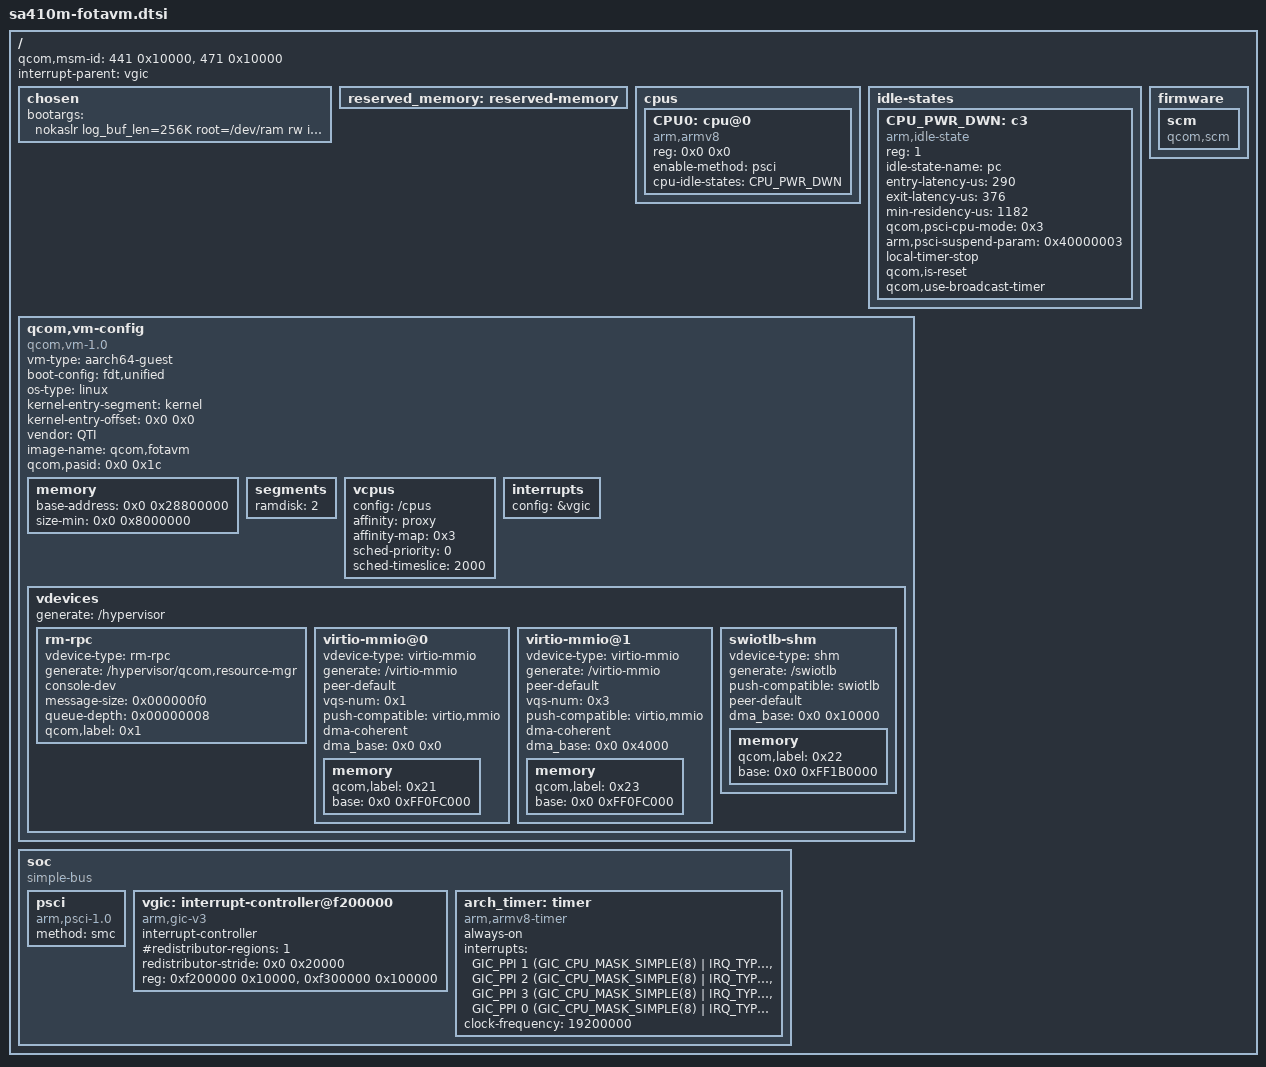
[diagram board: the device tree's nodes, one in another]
#include <dt-bindings/interrupt-controller/arm-gic.h>

/ {
	#address-cells = <0x2>;
	#size-cells = <0x2>;
	qcom,msm-id = <441 0x10000>, <471 0x10000>;
	interrupt-parent = <&vgic>;

	chosen {
		bootargs = "nokaslr log_buf_len=256K root=/dev/ram rw init=/init console=hvc0 loglevel=8";
	};

	reserved_memory: reserved-memory {
		#address-cells = <2>;
		#size-cells = <2>;
		ranges;
	};

	cpus {
		#address-cells = <0x2>;
		#size-cells = <0x0>;

		CPU0: cpu@0 {
			compatible = "arm,armv8";
			reg = <0x0 0x0>;
			device_type = "cpu";
			enable-method = "psci";
			cpu-idle-states = <&CPU_PWR_DWN>;
		};
	};

	idle-states {
		CPU_PWR_DWN: c3 {  /* C3 */
			reg = <1>;
			compatible = "arm,idle-state";
			idle-state-name = "pc";
			entry-latency-us = <290>;
			exit-latency-us = <376>;
			min-residency-us = <1182>;
			qcom,psci-cpu-mode = <0x3>;
			arm,psci-suspend-param = <0x40000003>;
			local-timer-stop;
			qcom,is-reset;
			qcom,use-broadcast-timer;
		};
	};

	qcom,vm-config {
		compatible = "qcom,vm-1.0";
		vm-type = "aarch64-guest";
		boot-config = "fdt,unified";
		os-type = "linux";
		kernel-entry-segment = "kernel";
		kernel-entry-offset = <0x0 0x0>;
		vendor = "QTI";
		image-name = "qcom,fotavm";
		qcom,pasid = <0x0 0x1c>;

		memory {
			#address-cells = <0x2>;
			#size-cells = <0x0>;
			base-address = <0x0 0x28800000>;
			size-min = <0x0 0x8000000>; /* 128 MB */
		};

		segments {
			ramdisk = <2>; /* 8 MB */
		};

		vcpus {
			config = "/cpus";
			affinity = "proxy";
			affinity-map = <0x3>;
			sched-priority = <0>;       /* relative to PVM */
			sched-timeslice = <2000>;   /* in ms */
		};

		interrupts {
			config = &vgic;
		};

		vdevices {
			generate = "/hypervisor";
			rm-rpc {
				vdevice-type = "rm-rpc";
				generate = "/hypervisor/qcom,resource-mgr";
				console-dev;
				message-size = <0x000000f0>;
				queue-depth = <0x00000008>;
				qcom,label = <0x1>;
			};

			virtio-mmio@0 {
				vdevice-type = "virtio-mmio";
				generate = "/virtio-mmio";
				peer-default;
				vqs-num = <0x1>;
				push-compatible = "virtio,mmio";
				dma-coherent;
				dma_base = <0x0 0x0>;
				memory {
					qcom,label = <0x21>;	//for system.img
					#address-cells = <0x2>;
					base = <0x0 0xFF0FC000>;
				};
			};

			virtio-mmio@1 {
				vdevice-type = "virtio-mmio";
				generate = "/virtio-mmio";
				peer-default;
				vqs-num = <0x3>;
				push-compatible = "virtio,mmio";
				dma-coherent;
				dma_base = <0x0 0x4000>;
				memory {
					qcom,label = <0x23>;	//for net
					#address-cells = <0x2>;
					base = <0x0 0xFF0FC000>;
				};
			};

			swiotlb-shm {
				vdevice-type = "shm";
				generate = "/swiotlb";
				push-compatible = "swiotlb";
				peer-default;
				dma_base = <0x0 0x10000>;
				memory {
					qcom,label = <0x22>;
					#address-cells = <0x2>;
					base = <0x0 0xFF1B0000>;
				};
			};
		};
	};

	firmware: firmware {
		scm {
			compatible = "qcom,scm";
		};
	};

	soc: soc { };
};

&soc {
	#address-cells = <1>;
	#size-cells = <1>;
	ranges = <0 0 0 0xffffffff>;
	compatible = "simple-bus";

	psci {
		compatible = "arm,psci-1.0";
		method = "smc";
	};

	vgic: interrupt-controller@f200000 {
		compatible = "arm,gic-v3";
		interrupt-controller;
		#interrupt-cells = <0x3>;
		#redistributor-regions = <1>;
		redistributor-stride = <0x0 0x20000>;
		reg = <0xf200000 0x10000>,     /* GICD */
		      <0xf300000 0x100000>;    /* GICR * 8 */
	};

	arch_timer: timer {
		compatible = "arm,armv8-timer";
		always-on;
		interrupts = <GIC_PPI 1 (GIC_CPU_MASK_SIMPLE(8) | IRQ_TYPE_LEVEL_LOW)>,
			     <GIC_PPI 2 (GIC_CPU_MASK_SIMPLE(8) | IRQ_TYPE_LEVEL_LOW)>,
			     <GIC_PPI 3 (GIC_CPU_MASK_SIMPLE(8) | IRQ_TYPE_LEVEL_LOW)>,
			     <GIC_PPI 0 (GIC_CPU_MASK_SIMPLE(8) | IRQ_TYPE_LEVEL_LOW)>;
		clock-frequency = <19200000>;
	};
};
